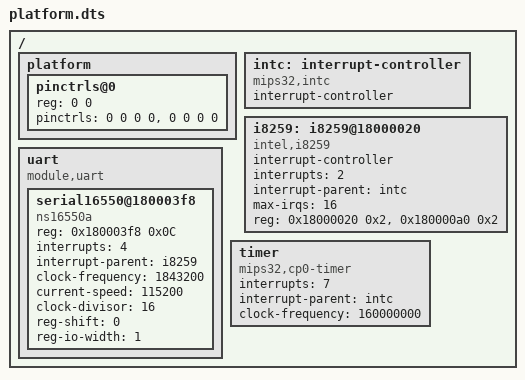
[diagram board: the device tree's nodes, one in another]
/*
 * SPDX-License-Identifier: Apache-2.0
 * Copyright (c) 2019 KapaXL (kapa.xl@outlook.com)
 */

/dts-v1/;

#include "memory.dtsi"

/ {
	platform {
		#address-cells = <1>;
		#size-cells = <0>;

		pinctrls@0 {
			reg = <0 0>;

			/*
			 * cells information
			 * 0: reg offset,
			 * 1: first bit position,
			 * 2: number of bits,
			 * 3: value
			 */
			/* unnecessary for QEMU */
			pinctrls = <0 0 0 0>, <0 0 0 0>;
		};
	};

	/* interrupt-controller: CPU side */
	intc: interrupt-controller {
		compatible = "mips32,intc";

		interrupt-controller;

		#interrupt-cells = <1>;
		#address-cells = <1>;
	};

	/* interrupt-controller: SoC side */
	i8259: i8259@18000020 {
		compatible = "intel,i8259";

		interrupt-controller;

		#interrupt-cells = <1>;

		interrupts = <2>; /* connects to CPU IP2 */
		interrupt-parent = <&intc>;

		max-irqs = <16>;

		reg = <0x18000020 0x2>, /* master */
			<0x180000a0 0x2>;  /* slave */
	};

	uart {
		compatible = "module,uart";
		#address-cells = <1>;
		#size-cells = <1>;

		serial16550@180003f8 {
			compatible = "ns16550a";
			reg = <0x180003f8 0x0C>;
			interrupts = <4>;
			interrupt-parent = <&i8259>;
			clock-frequency = <1843200>;
			current-speed = <115200>;
			clock-divisor = <16>;
			reg-shift = <0>;
			reg-io-width = <1>;
		};
	};

	timer {
		compatible = "mips32,cp0-timer";
		interrupts = <7>;
		interrupt-parent = <&intc>;
		clock-frequency = <160000000>;
	};
};
